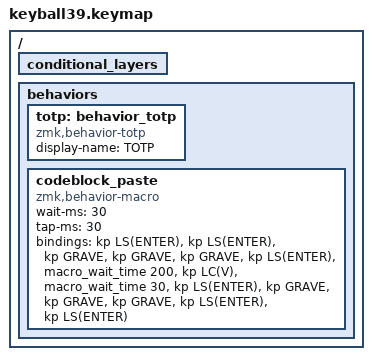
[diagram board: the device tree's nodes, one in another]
#define CONFIG_WIRELESS

// Default ZMK_BASE_LAYER for non-Base layers: positions 30 and 38 are &none.
// Base redefines this macro below to put `&mo SYS` at position 30 and
// `&kp PSCRN` at position 38, so both keys are only active on Base.
#define ZMK_BASE_LAYER(name, LT, RT, LM, RM, LB, RB, LH, RH)                   \
    ZMK_LAYER(                                                                 \
        name,                                                                  \
                 LT RT                                                         \
                 LM RM                                                         \
                 LB RB                                                         \
          &none &none &none &none LH RH &none                                  \
    )

/*                              39 KEY MATRIX / LAYOUT MAPPING

  ╭────────────────────────┬────────────────────────╮ ╭─────────────────────────┬─────────────────────────╮
  │  0   1   2   3   4     │      5   6   7   8   9 │ │ LT4 LT3 LT2 LT1 LT0     │     RT0 RT1 RT2 RT3 RT4 │
  │ 10  11  12  13  14     │     15  16  17  18  19 │ │ LM4 LM3 LM2 LM1 LM0     │     RM0 RM1 RM2 RM3 RM4 │
  │ 20  21  22  23  24     │     25  26  27  28  29 │ │ LB4 LB3 LB2 LB1 LB0     │     RB0 RB1 RB2 RB3 RB4 │
  │ 30  31  32  33  34  35 │ 36  37              38 │ │ LH5 LH4 LH3 LH2 LH1 LH0 │ RH0 RH1             RH2 │
  ╰────────────────────────┴────────────────────────╯ ╰─────────────────────────┴─────────────────────────╯             */

#pragma once

#define LT0  4  // left-top row
#define LT1  3
#define LT2  2
#define LT3  1
#define LT4  0

#define RT0  5  // right-top row
#define RT1  6
#define RT2  7
#define RT3  8
#define RT4  9

#define LM0 14  // left-middle row
#define LM1 13
#define LM2 12
#define LM3 11
#define LM4 10

#define RM0 15  // right-middle row
#define RM1 16
#define RM2 17
#define RM3 18
#define RM4 19

#define LB0 24  // left-bottom row
#define LB1 23
#define LB2 22
#define LB3 21
#define LB4 20

#define RB0 25  // right-bottom row
#define RB1 26
#define RB2 27
#define RB3 28
#define RB4 29

#define LH0 35  // left thumb keys
#define LH1 34
#define LH2 33
#define LH3 32
#define LH4 31
#define LH5 30

#define RH0 36  // right thumb keys
#define RH1 37
#define RH2 38

// Upstream removed these from base.keymap (they now live in zmk-helpers/key-labels/N.h,
// but no header matches the Keyball39's 30 alphas + 9 thumbs layout, so define inline).
#define KEYS_L LT0 LT1 LT2 LT3 LT4 LM0 LM1 LM2 LM3 LM4 LB0 LB1 LB2 LB3 LB4
#define KEYS_R RT0 RT1 RT2 RT3 RT4 RM0 RM1 RM2 RM3 RM4 RB0 RB1 RB2 RB3 RB4
#define THUMBS LH0 LH1 LH2 LH3 LH4 LH5 RH0 RH1 RH2

#include "base.keymap"

// Delete the FN+NUM -> SYS conditional layer that base.keymap installs via
// ZMK_CONDITIONAL_LAYER(sys, FN NUM, SYS). ZMK's conditional-layer listener
// runs on every layer state change and forcibly DEACTIVATES any "then-layer"
// (here SYS) whenever its if-condition (here FN+NUM both active) is not met
// — which collides with our direct `&mo SYS` activator on position 30 (LH5).
// Pressing LH5 activates Sys for one instant, then the listener kills it
// because FN+NUM aren't held, so Sys never visibly turns on. Removing the
// conditional rule restores normal &mo SYS behavior. We don't lose
// functionality since we have a dedicated Sys activator now.
//
// A `#define ZMK_CONDITIONAL_LAYER ...` before the include doesn't work
// because base.keymap includes <zmk-helpers/helper.h> which redefines the
// macro AFTER our override. /delete-node/ at the DT level is what actually
// sticks.
/ {
    conditional_layers {
        /delete-node/ tri_layer_sys;
    };
};

// On-device TOTP behavior node. The DT node is defined unconditionally on
// both halves (the keymap is shared, and Kconfig-derived CONFIG_* macros
// aren't visible to the keymap preprocessor — only manual #defines are, so
// `#if defined(CONFIG_SHIELD_KEYBALL39_RIGHT)` silently evaluates false in
// this file). The C driver in behavior_totp.c is still gated to the right
// shield via CMakeLists; on a left build the device just isn't instantiated.
//
// Current bindings: Sys layer Y / U / I are `&totp 0 / 5 / 15` for testing.
// Activate Sys (hold LH5 = leftmost left thumb) then press Y, U, or I to
// type the TOTP for that slot. The host pushes time automatically via the
// CLI; if you've power-cycled and haven't run `keyball39-totp list` since,
// &totp will log "host time not yet synced" and refuse to type.
/ {
    behaviors {
        totp: behavior_totp {
            compatible = "zmk,behavior-totp";
            #binding-cells = <1>;
            display-name = "TOTP";
        };
    };
};

// Macro bound to position 33 (LH2, the key immediately left of the Nav thumb
// at LH1). Wraps the clipboard contents in a Markdown fenced code block for an
// AI-agent chat box where Shift+Enter inserts a newline (plain Enter submits).
// Each ``` fence sits on its own line for valid Markdown, with a blank line
// padding the block top and bottom:
//   S+Ret ×2 → ``` → S+Ret → Ctrl+V (paste) → S+Ret → ``` → S+Ret ×2
// yielding (with leading/trailing blank lines):
//
//   ```
//   <clipboard>
//   ```
//
// Shift+Enter is the near-universal "newline without submitting" chord in web
// chat UIs (ChatGPT, Claude, Slack, Discord, ...). It replaced Ctrl+J (ASCII
// LF), which is the terminal convention but is NOT handled by most browser
// text boxes — several of them treat Ctrl+J as the browser's own Downloads
// shortcut instead. GRAVE is the unshifted backtick; three in a row form the
// ``` fence.
//
// NOTE: Shift is a live modifier here, so this macro must not be fired while
// another shift-like behavior is engaged (caps-word, a sticky shift from Magic
// Shift). The fences would come out as ~~~ (shifted backtick) instead of ```.
//
// Timing matters because this is a BLE keyboard. tap-ms/wait-ms must comfortably
// exceed the HID connection interval (~15 ms) or the press+release of a key can
// land inside a single interval and get coalesced/dropped — the old 5 ms values
// caused "six backticks, no paste" (chorded keys that must hold a modifier
// across the tap are the most fragile, which now includes every Shift+Enter as
// well as Ctrl+V). 30 ms gives ~2x margin. The `&macro_wait_time 200` after
// Ctrl+V lets the host finish the (possibly large) paste before the closing
// fence is typed, so the trailing ``` isn't swallowed. If it's still
// occasionally flaky on a slow app or huge clipboard, raise that 200 ms.
ZMK_MACRO(codeblock_paste,
    wait-ms = <30>;
    tap-ms = <30>;
    bindings = <&kp LS(ENTER) &kp LS(ENTER)
                &kp GRAVE &kp GRAVE &kp GRAVE
                &kp LS(ENTER)
                &macro_wait_time 200
                &kp LC(V)
                &macro_wait_time 30
                &kp LS(ENTER)
                &kp GRAVE &kp GRAVE &kp GRAVE
                &kp LS(ENTER) &kp LS(ENTER)>;
)

// TOTP layer index — comes after base.keymap's
// DEF/PLAIN/NAV/FN/NUM/SYS/MOUSE (0..6) in declaration order, so this is 7.
// Must match the order ZMK_LAYER(TOTP, ...) is emitted below.
#define TOTP 7

// Redefine ZMK_BASE_LAYER so the Base layer below gets `&mo SYS` at position
// 30 (LH5), `&mo TOTP` at position 31 (LH4 — the key immediately right of the
// Sys activator), `&tog PLAIN` at position 32 (LH3 — right of the TOTP
// activator; this was the one unassigned key on the board),
// `&codeblock_paste` at position 33 (LH2 — the key immediately left of the Nav
// thumb), plus `&kp PSCRN` at position 38. Non-Base layers
// (Nav/Fn/Num/Sys/Mouse/TOTP) keep the &none from the earlier definition.
// DT property merging means this second `layer_Base { bindings = <...>; }`
// overrides the Colemak Base from base.keymap.
#undef ZMK_BASE_LAYER
#define ZMK_BASE_LAYER(name, LT, RT, LM, RM, LB, RB, LH, RH)                   \
    ZMK_LAYER(                                                                 \
        name,                                                                  \
                 LT RT                                                         \
                 LM RM                                                         \
                 LB RB                                                         \
          &mo SYS &mo TOTP &tog PLAIN &codeblock_paste LH RH &kp PSCRN        \
    )

// moving back to QWERTY
ZMK_BASE_LAYER(Base,
//╭─────────────┬─────────────┬─────────────┬─────────────┬─────────────╮ ╭─────────────┬─────────────┬─────────────┬─────────────┬─────────────╮
    &kp Q         &kp W         &kp E         &kp R         &kp T       ,   &kp Y         &kp U         &kp I         &kp O         &kp P       ,
//├─────────────┼─────────────┼─────────────┼─────────────┼─────────────┤ ├─────────────┼─────────────┼─────────────┼─────────────┼─────────────┤
    &hml LGUI A   &hml LALT S   &hml LSHFT D  &hml LCTRL F  &kp G       ,   &kp H         &hmr LCTRL J  &hmr RSHFT K  &hmr LALT L   &hmr LGUI SQT ,
//├─────────────┼─────────────┼─────────────┼─────────────┼─────────────┤ ├─────────────┼─────────────┼─────────────┼─────────────┼─────────────┤
    &kp Z         &kp X         &kp C         &kp V         &kp B       ,   &kp N         &kp M         &comma_morph  &dot_morph    &qexcl      ,
//╰─────────────┼─────────────┴─────────────┼─────────────┼─────────────┤ ├─────────────┼─────────────┼─────────────┴───────────────────────────╯
                                              &lt_spc NAV 0 &lt FN RET  ,   MAGIC_SHIFT   SMART_NUM
//                                          ╰─────────────┴─────────────╯ ╰─────────────┴─────────────╯
)

// return single quote that was erased by letter P
// ZMK_COMBO(sqt,  &kp SQT,     RT3 RT4,         DEF    , COMBO_TERM_FAST, COMBO_IDLE_FAST)

// Plain layer (index 1) — homerow mods off. base.keymap already emitted this
// layer with the Colemak homerow; re-emit it here with the QWERTY letters so
// the plain taps match this fork's Base layer. DT property merging replaces the
// `bindings` property wholesale, exactly like the Base override above.
//
// Toggled by `&tog PLAIN` at position 32. Every non-homerow key is `___`
// (&trans) so Base shows through — crucially including position 32 itself, or
// the layer could never be switched back off, and the thumb cluster, so layer
// access still works while Plain is on.
//
// Note this needs its OWN macro variant: the Base variant above would put
// `&mo SYS`/`&tog PLAIN`/`&codeblock_paste`/`&kp PSCRN` here (harmless but
// redundant), while the non-Base variant further down would put `&none` at
// those positions — which would dead-key the toggle and trap you on Plain.
#undef ZMK_BASE_LAYER
#define ZMK_BASE_LAYER(name, LT, RT, LM, RM, LB, RB, LH, RH)                   \
    ZMK_LAYER(                                                                 \
        name,                                                                  \
                 LT RT                                                         \
                 LM RM                                                         \
                 LB RB                                                         \
          ___ ___ ___ ___ LH RH ___                                            \
    )

ZMK_BASE_LAYER(Plain,
//╭─────────────┬─────────────┬─────────────┬─────────────┬─────────────╮ ╭─────────────┬─────────────┬─────────────┬─────────────┬─────────────╮
    ___           ___           ___           ___           ___         ,   ___           ___           ___           ___           ___         ,
//├─────────────┼─────────────┼─────────────┼─────────────┼─────────────┤ ├─────────────┼─────────────┼─────────────┼─────────────┼─────────────┤
    &kp A         &kp S         &kp D         &kp F         ___         ,   ___           &kp J         &kp K         &kp L         &kp SQT     ,
//├─────────────┼─────────────┼─────────────┼─────────────┼─────────────┤ ├─────────────┼─────────────┼─────────────┼─────────────┼─────────────┤
    ___           ___           ___           ___           ___         ,   ___           ___           ___           ___           ___         ,
//╰─────────────┼─────────────┴─────────────┼─────────────┼─────────────┤ ├─────────────┼─────────────┼─────────────┴───────────────────────────╯
                                              ___           ___         ,   ___           ___
//                                          ╰─────────────┴─────────────╯ ╰─────────────┴─────────────╯
)

// TOTP layer: mirrors the Fn layer's F-key positions on the left half so the
// muscle memory is "same finger position as F<N>, but on TOTP layer". Activated
// by `&mo TOTP` at position 31 (LH4 — right of the Sys activator).
//
//   Position →    Fn layer    TOTP layer
//   LT4           F12         &totp 12
//   LT3           F7          &totp 7
//   LT2           F8          &totp 8
//   LT1           F9          &totp 9
//   LM4           F11         &totp 11
//   LM3           F4          &totp 4
//   LM2           F5          &totp 5
//   LM1           F6          &totp 6
//   LB4           F10         &totp 10
//   LB3           F1          &totp 1
//   LB2           F2          &totp 2
//   LB1           F3          &totp 3
//
// Slot 0 isn't reachable from this layer (Fn has no F0). Provision into 1-12
// via the CLI: `keyball39-totp write 1 <label> <base32>`.
#undef ZMK_BASE_LAYER
#define ZMK_BASE_LAYER(name, LT, RT, LM, RM, LB, RB, LH, RH)                   \
    ZMK_LAYER(                                                                 \
        name,                                                                  \
                 LT RT                                                         \
                 LM RM                                                         \
                 LB RB                                                         \
          &none &none &none &none LH RH &none                                  \
    )

// `#undef TOTP` before the layer definition so `ZMK_BASE_LAYER(TOTP, ...)`
// does NOT preprocessor-substitute TOTP→6. Without this, ZMK_LAYER's
// internal `##` paste produces `layer_6` with `display-name = "6"`. After
// the undef, the layer-name token stays literal — yielding `layer_TOTP`
// with the desired auto-generated `display-name = "TOTP"` (matches the
// OLED, no DT override needed, no yaml-side label override needed for the
// keymap-drawer SVG either). This dance is necessary because we want the
// activator macro `&mo TOTP` to stay readable in the Base layer above (so
// TOTP must be defined as 6 there), while the layer-name token here needs
// to remain the literal string `TOTP`. The macro has done its job by this
// point and is no longer referenced.
#undef TOTP

ZMK_BASE_LAYER(TOTP,
//╭─────────────┬─────────────┬─────────────┬─────────────┬─────────────╮ ╭─────────────┬─────────────┬─────────────┬─────────────┬─────────────╮
    &totp 12      &totp 7       &totp 8       &totp 9       ___         ,   ___           ___           ___           ___           ___         ,
//├─────────────┼─────────────┼─────────────┼─────────────┼─────────────┤ ├─────────────┼─────────────┼─────────────┼─────────────┼─────────────┤
    &totp 11      &totp 4       &totp 5       &totp 6       ___         ,   ___           ___           ___           ___           ___         ,
//├─────────────┼─────────────┼─────────────┼─────────────┼─────────────┤ ├─────────────┼─────────────┼─────────────┼─────────────┼─────────────┤
    &totp 10      &totp 1       &totp 2       &totp 3       ___         ,   ___           ___           ___           ___           ___         ,
//╰─────────────┼─────────────┴─────────────┼─────────────┼─────────────┤ ├─────────────┼─────────────┼─────────────┴───────────────────────────╯
                                              ___           ___         ,   ___           ___
//                                          ╰─────────────┴─────────────╯ ╰─────────────┴─────────────╯
)
